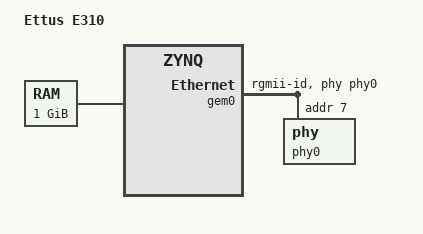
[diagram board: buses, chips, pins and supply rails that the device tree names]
/include/ "zynq.dtsi"

/ {
	model = "Ettus E310";

	memory {
		device_type = "memory";
		reg = <0x000000000 0x40000000>;
	};
	
	aliases: aliases {
		ethernet0 = &gem0;
		serial0 = &uart0;
		serial1 = &uart1;
	};

	chosen {
//		bootargs = "console=ttyPS0,115200 root=/dev/ram rw initrd=0x1100000,33M ip=:::::eth0:dhcp earlyprintk";
		bootargs = "console=ttyPS0,115200 root=/dev/mmcblk0p2 rw earlyprintk rootfstype=ext4 rootwait";
//		linux,stdout-path = "/amba@0/uart@E0001000";
		linux,stdout-path = "serial0:115200n8";
		stdout-path = "serial0:115200n8";
	};
};

&gem0 {
	phy-handle = <&phy0>;
	phy-mode = "rgmii-id";

	phy0: phy@7 {
		device_type = "ethernet-phy";
		reg = <0x7>;
	};
};
